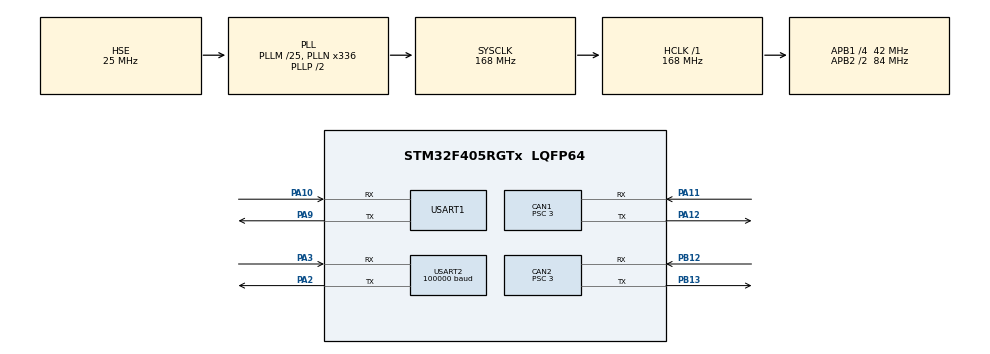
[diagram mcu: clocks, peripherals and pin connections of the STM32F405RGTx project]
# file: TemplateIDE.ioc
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CAN1.BS1=CAN_BS1_9TQ
CAN1.BS2=CAN_BS2_4TQ
CAN1.CalculateBaudRate=1000000
CAN1.CalculateTimeBit=999.99
CAN1.CalculateTimeQuantum=71.42857142857143
CAN1.Prescaler=3
CAN2.BS1=CAN_BS1_9TQ
CAN2.BS2=CAN_BS2_4TQ
CAN2.CalculateBaudRate=1000000
CAN2.CalculateTimeBit=999.99
CAN2.CalculateTimeQuantum=71.42857142857143
CAN2.Prescaler=3
FREERTOS.INCLUDE_vTaskDelayUntil=1
FREERTOS.Tasks01=defaultTask,0,128,StartDefaultTask,Default,NULL,Dynamic,NULL,NULL
Mcu.Family=STM32F4
Mcu.Name=STM32F405RGTx
Mcu.Package=LQFP64
NVIC.CAN1_RX0_IRQn=true\:5\:0\:false\:false\:true\:true\:true\:true
NVIC.CAN1_RX1_IRQn=true\:5\:0\:false\:false\:true\:true\:true\:true
NVIC.CAN2_RX0_IRQn=true\:5\:0\:false\:false\:true\:true\:true\:true
NVIC.CAN2_RX1_IRQn=true\:5\:0\:false\:false\:true\:true\:true\:true
NVIC.PriorityGroup=NVIC_PRIORITYGROUP_4
NVIC.TIM4_IRQn=true\:5\:0\:false\:false\:true\:true\:true\:true
NVIC.TIM7_IRQn=true\:0\:0\:false\:false\:true\:false\:false\:true
NVIC.TimeBase=TIM7_IRQn
NVIC.TimeBaseIP=TIM7
NVIC.USART1_IRQn=true\:5\:0\:false\:false\:true\:true\:true\:true
NVIC.USART2_IRQn=true\:5\:0\:false\:false\:true\:true\:true\:true
PA10.Mode=Asynchronous
PA10.Signal=USART1_RX
PA11.Mode=CAN_Activate
PA11.Signal=CAN1_RX
PA12.Mode=CAN_Activate
PA12.Signal=CAN1_TX
PA13.Mode=Serial_Wire
PA13.Signal=SYS_JTMS-SWDIO
PA14.Mode=Serial_Wire
PA14.Signal=SYS_JTCK-SWCLK
PA2.Mode=Asynchronous
PA2.Signal=USART2_TX
PA3.Mode=Asynchronous
PA3.Signal=USART2_RX
PA9.Mode=Asynchronous
PA9.Signal=USART1_TX
PB12.Mode=CAN_Activate
PB12.Signal=CAN2_RX
PB13.Mode=CAN_Activate
PB13.Signal=CAN2_TX
PH0-OSC_IN.Mode=HSE-External-Oscillator
PH0-OSC_IN.Signal=RCC_OSC_IN
PH1-OSC_OUT.Mode=HSE-External-Oscillator
PH1-OSC_OUT.Signal=RCC_OSC_OUT
ProjectManager.HeapSize=0x200
ProjectManager.StackSize=0x400
ProjectManager.TargetToolchain=STM32CubeIDE
RCC.48MHZClocksFreq_Value=84000000
RCC.AHBFreq_Value=168000000
RCC.APB1CLKDivider=RCC_HCLK_DIV4
RCC.APB1Freq_Value=42000000
RCC.APB1TimFreq_Value=84000000
RCC.APB2CLKDivider=RCC_HCLK_DIV2
RCC.APB2Freq_Value=84000000
RCC.APB2TimFreq_Value=168000000
RCC.CortexFreq_Value=168000000
RCC.HCLKFreq_Value=168000000
RCC.HSE_VALUE=25000000
RCC.HSI_VALUE=16000000
RCC.LSE_VALUE=32768
RCC.PLLM=25
RCC.PLLN=336
RCC.PLLSourceVirtual=RCC_PLLSOURCE_HSE
RCC.SYSCLKFreq_VALUE=168000000
RCC.SYSCLKSource=RCC_SYSCLKSOURCE_PLLCLK
RCC.VCOOutputFreq_Value=336000000
TIM4.Prescaler=84-1
USART1.VirtualMode=VM_ASYNC
USART2.BaudRate=100000
USART2.Parity=PARITY_EVEN
USART2.VirtualMode=VM_ASYNC
USART2.WordLength=WORDLENGTH_9B
VP_FREERTOS_VS_CMSIS_V1.Mode=CMSIS_V1
VP_SYS_VS_tim7.Mode=TIM7
VP_TIM4_VS_ClockSourceINT.Mode=Internal
board=custom

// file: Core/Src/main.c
/* USER CODE BEGIN Header */
/**
  ******************************************************************************
  * @file           : main.c
  * @brief          : Main program body
  ******************************************************************************
  * @attention
  *
  * <h2><center>&copy; Copyright (c) 2021 STMicroelectronics.
  * All rights reserved.</center></h2>
  *
  * This software component is licensed by ST under Ultimate Liberty license
  * SLA0044, the "License"; You may not use this file except in compliance with
  * the License. You may obtain a copy of the License at:
  *                             www.st.com/SLA0044
  *
  ******************************************************************************
  */
/* USER CODE END Header */
#include "main.h"
#include "cmsis_os.h"

/* USER CODE BEGIN Includes */
#include "app.h"
#include "SRML.h"
/* USER CODE END Includes */

CAN_HandleTypeDef hcan1;
CAN_HandleTypeDef hcan2;

TIM_HandleTypeDef htim4;

UART_HandleTypeDef huart1;
UART_HandleTypeDef huart2;

osThreadId defaultTaskHandle;

void SystemClock_Config(void);
static void MX_GPIO_Init(void);
static void MX_CAN1_Init(void);
static void MX_CAN2_Init(void);
static void MX_TIM4_Init(void);
static void MX_USART1_UART_Init(void);
static void MX_USART2_UART_Init(void);
void StartDefaultTask(void const * argument);

int main(void)
{

  /* MCU Configuration--------------------------------------------------------*/

  /* Reset of all peripherals, Initializes the Flash interface and the Systick. */
  HAL_Init();

  /* Configure the system clock */
  SystemClock_Config();

  /* Initialize all configured peripherals */
  MX_GPIO_Init();
  MX_CAN1_Init();
  MX_CAN2_Init();
  MX_TIM4_Init();
  MX_USART1_UART_Init();
  MX_USART2_UART_Init();
  /* USER CODE BEGIN 2 */
  App_Device_Init();
  /* USER CODE END 2 */

  /* Create the thread(s) */
  /* definition and creation of defaultTask */
  osThreadDef(defaultTask, StartDefaultTask, osPriorityNormal, 0, 128);
  defaultTaskHandle = osThreadCreate(osThread(defaultTask), NULL);

  /* Start scheduler */
  osKernelStart();

  /* We should never get here as control is now taken by the scheduler */
  /* Infinite loop */
  while (1)
  {

  }
}

void SystemClock_Config(void)
{
  RCC_OscInitTypeDef RCC_OscInitStruct = {0};
  RCC_ClkInitTypeDef RCC_ClkInitStruct = {0};

  /** Configure the main internal regulator output voltage
  */
  __HAL_RCC_PWR_CLK_ENABLE();
  __HAL_PWR_VOLTAGESCALING_CONFIG(PWR_REGULATOR_VOLTAGE_SCALE1);
  /** Initializes the RCC Oscillators according to the specified parameters
  * in the RCC_OscInitTypeDef structure.
  */
  RCC_OscInitStruct.OscillatorType = RCC_OSCILLATORTYPE_HSE;
  RCC_OscInitStruct.HSEState = RCC_HSE_ON;
  RCC_OscInitStruct.PLL.PLLState = RCC_PLL_ON;
  RCC_OscInitStruct.PLL.PLLSource = RCC_PLLSOURCE_HSE;
  RCC_OscInitStruct.PLL.PLLM = 25;
  RCC_OscInitStruct.PLL.PLLN = 336;
  RCC_OscInitStruct.PLL.PLLP = RCC_PLLP_DIV2;
  RCC_OscInitStruct.PLL.PLLQ = 4;
  if (HAL_RCC_OscConfig(&RCC_OscInitStruct) != HAL_OK)
  {
    Error_Handler();
  }
  /** Initializes the CPU, AHB and APB buses clocks
  */
  RCC_ClkInitStruct.ClockType = RCC_CLOCKTYPE_HCLK|RCC_CLOCKTYPE_SYSCLK
                              |RCC_CLOCKTYPE_PCLK1|RCC_CLOCKTYPE_PCLK2;
  RCC_ClkInitStruct.SYSCLKSource = RCC_SYSCLKSOURCE_PLLCLK;
  RCC_ClkInitStruct.AHBCLKDivider = RCC_SYSCLK_DIV1;
  RCC_ClkInitStruct.APB1CLKDivider = RCC_HCLK_DIV4;
  RCC_ClkInitStruct.APB2CLKDivider = RCC_HCLK_DIV2;

  if (HAL_RCC_ClockConfig(&RCC_ClkInitStruct, FLASH_LATENCY_5) != HAL_OK)
  {
    Error_Handler();
  }
}

static void MX_CAN1_Init(void)
{

  hcan1.Instance = CAN1;
  hcan1.Init.Prescaler = 3;
  hcan1.Init.Mode = CAN_MODE_NORMAL;
  hcan1.Init.SyncJumpWidth = CAN_SJW_1TQ;
  hcan1.Init.TimeSeg1 = CAN_BS1_9TQ;
  hcan1.Init.TimeSeg2 = CAN_BS2_4TQ;
  hcan1.Init.TimeTriggeredMode = DISABLE;
  hcan1.Init.AutoBusOff = DISABLE;
  hcan1.Init.AutoWakeUp = DISABLE;
  hcan1.Init.AutoRetransmission = DISABLE;
  hcan1.Init.ReceiveFifoLocked = DISABLE;
  hcan1.Init.TransmitFifoPriority = DISABLE;
  if (HAL_CAN_Init(&hcan1) != HAL_OK)
  {
    Error_Handler();
  }

}

static void MX_CAN2_Init(void)
{

  hcan2.Instance = CAN2;
  hcan2.Init.Prescaler = 3;
  hcan2.Init.Mode = CAN_MODE_NORMAL;
  hcan2.Init.SyncJumpWidth = CAN_SJW_1TQ;
  hcan2.Init.TimeSeg1 = CAN_BS1_9TQ;
  hcan2.Init.TimeSeg2 = CAN_BS2_4TQ;
  hcan2.Init.TimeTriggeredMode = DISABLE;
  hcan2.Init.AutoBusOff = DISABLE;
  hcan2.Init.AutoWakeUp = DISABLE;
  hcan2.Init.AutoRetransmission = DISABLE;
  hcan2.Init.ReceiveFifoLocked = DISABLE;
  hcan2.Init.TransmitFifoPriority = DISABLE;
  if (HAL_CAN_Init(&hcan2) != HAL_OK)
  {
    Error_Handler();
  }

}

static void MX_TIM4_Init(void)
{

  TIM_ClockConfigTypeDef sClockSourceConfig = {0};
  TIM_MasterConfigTypeDef sMasterConfig = {0};

  htim4.Instance = TIM4;
  htim4.Init.Prescaler = 84-1;
  htim4.Init.CounterMode = TIM_COUNTERMODE_UP;
  htim4.Init.Period = 65535;
  htim4.Init.ClockDivision = TIM_CLOCKDIVISION_DIV1;
  htim4.Init.AutoReloadPreload = TIM_AUTORELOAD_PRELOAD_DISABLE;
  if (HAL_TIM_Base_Init(&htim4) != HAL_OK)
  {
    Error_Handler();
  }
  sClockSourceConfig.ClockSource = TIM_CLOCKSOURCE_INTERNAL;
  if (HAL_TIM_ConfigClockSource(&htim4, &sClockSourceConfig) != HAL_OK)
  {
    Error_Handler();
  }
  sMasterConfig.MasterOutputTrigger = TIM_TRGO_RESET;
  sMasterConfig.MasterSlaveMode = TIM_MASTERSLAVEMODE_DISABLE;
  if (HAL_TIMEx_MasterConfigSynchronization(&htim4, &sMasterConfig) != HAL_OK)
  {
    Error_Handler();
  }

}

static void MX_USART1_UART_Init(void)
{

  huart1.Instance = USART1;
  huart1.Init.BaudRate = 115200;
  huart1.Init.WordLength = UART_WORDLENGTH_8B;
  huart1.Init.StopBits = UART_STOPBITS_1;
  huart1.Init.Parity = UART_PARITY_NONE;
  huart1.Init.Mode = UART_MODE_TX_RX;
  huart1.Init.HwFlowCtl = UART_HWCONTROL_NONE;
  huart1.Init.OverSampling = UART_OVERSAMPLING_16;
  if (HAL_UART_Init(&huart1) != HAL_OK)
  {
    Error_Handler();
  }

}

static void MX_USART2_UART_Init(void)
{

  huart2.Instance = USART2;
  huart2.Init.BaudRate = 100000;
  huart2.Init.WordLength = UART_WORDLENGTH_9B;
  huart2.Init.StopBits = UART_STOPBITS_1;
  huart2.Init.Parity = UART_PARITY_EVEN;
  huart2.Init.Mode = UART_MODE_TX_RX;
  huart2.Init.HwFlowCtl = UART_HWCONTROL_NONE;
  huart2.Init.OverSampling = UART_OVERSAMPLING_16;
  if (HAL_UART_Init(&huart2) != HAL_OK)
  {
    Error_Handler();
  }

}

static void MX_GPIO_Init(void)
{

  /* GPIO Ports Clock Enable */
  __HAL_RCC_GPIOH_CLK_ENABLE();
  __HAL_RCC_GPIOA_CLK_ENABLE();
  __HAL_RCC_GPIOB_CLK_ENABLE();

}

void StartDefaultTask(void const * argument)
{
  /* USER CODE BEGIN 5 */
  App_Rtos_Init();
  /* Delete the default task. */
  osThreadTerminate (defaultTaskHandle);
  /* Infinite loop */
  for(;;)
  {
	  osDelay(1);
  }
  /* USER CODE END 5 */
}

 /**
  * @brief  Period elapsed callback in non blocking mode
  * @note   This function is called  when TIM7 interrupt took place, inside
  * HAL_TIM_IRQHandler(). It makes a direct call to HAL_IncTick() to increment
  * a global variable "uwTick" used as application time base.
  * @param  htim : TIM handle
  * @retval None
  */
void HAL_TIM_PeriodElapsedCallback(TIM_HandleTypeDef *htim)
{
  /* USER CODE BEGIN Callback 0 */
	if(htim->Instance == TIM4){
		Update_SystemTick();
	}
  /* USER CODE END Callback 0 */
  if (htim->Instance == TIM7) {
    HAL_IncTick();
  }
}

void Error_Handler(void)
{
  __disable_irq();
  while (1)
  {
  }
}

/************************ (C) COPYRIGHT STMicroelectronics *****END OF FILE****/
